# RS14100 register map
File version: 1.0
CPU: CM4 r0p1, little endian, MPU, FPU, 4 interrupt priority bits
Registers are 32-bit, read-write, reset 0x0 unless marked. A register's access mark holds for its fields unless they carry their own. Offsets are from the block's base; [hi:lo] are bit positions; {n}, {i} and the like mark numbered series.

## GSPI0 — GSPI, or Generic SPI, is a module which has been derived from QSPI. GSPI can act only as a master
Base 0x45030000
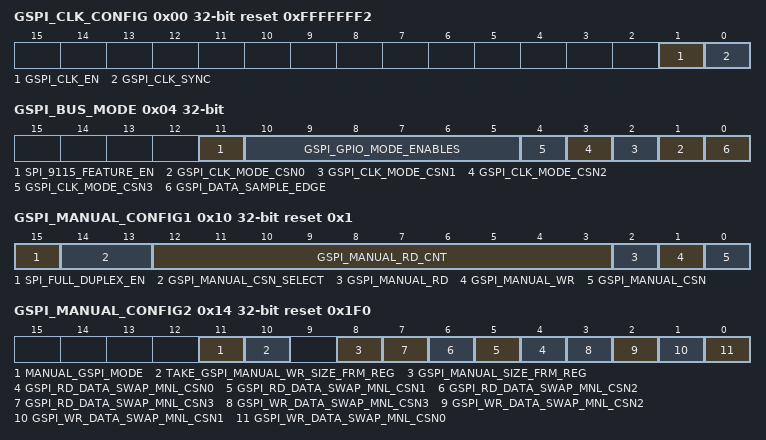
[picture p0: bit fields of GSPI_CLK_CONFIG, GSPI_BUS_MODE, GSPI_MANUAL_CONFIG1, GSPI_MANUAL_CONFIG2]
0x00 GSPI_CLK_CONFIG reset 0xFFFFFFF2 — GSPI Clock Configuration Register
  [1] GSPI_CLK_EN — GSPI clock enable
    0=Disable (Dynamic clock gating is enabled in side GSPI controller); 1=Enable (Full time clock is enabled for GSPI controller.)
  [0] GSPI_CLK_SYNC — If the clock frequency to FLASH (spi_clk) and SOC clk is same.
    0=Disable (Divided SOC clock is connected SCLK. Division value is programmable); 1=Enable (SCLK clock and SOC clock are same)
0x04 GSPI_BUS_MODE (reset mask 0x7FF)
  [11] SPI_9115_FEATURE_EN — 9115 specific features are enabled with this enable
  [10:5] GSPI_GPIO_MODE_ENABLES — These bits are used to map GSPI on GPIO pins
  [n+1] GSPI_CLK_MODE_CSN{n} (n=0..3)
    0=Disable (Mode 0, GSPI_CLK is low when GSPI_CS is high for chip select{n} (csn{n})); 1=Enable (Mode 3, GSPI_CLK is high when GSPI_CS is high for chip select{n} (csn{n}))
  [0] GSPI_DATA_SAMPLE_EDGE — Samples MISO data on clock edges. This should be ZERO for mode3 clock
    0=Disable (Pos edge of loop back spi_pad_clk); 1=Enable (Neg edge of loop back spi_pad_clk)
0x10 GSPI_MANUAL_CONFIG1 reset 0x1 — GSPI Manual Configuration 1 Register
  [15] SPI_FULL_DUPLEX_EN — Full duplex mode enable
    0=Disable (Full duplex mode disabled.); 1=Enable (Full duplex mode enabled)
  [14:13] GSPI_MANUAL_CSN_SELECT — Indicates which CSn is valid. Can be programmable in manual mode
  [12:3] GSPI_MANUAL_RD_CNT — Indicates total number of bytes to be read
  [2] GSPI_MANUAL_RD — Read enable for manual mode when CS is low
  [1] GSPI_MANUAL_WR — Write enable for manual mode when CS is low.
  [0] GSPI_MANUAL_CSN — SPI CS in manual mode
0x14 GSPI_MANUAL_CONFIG2 reset 0x1F0 — GSPI Manual Configuration 2 Register
  [11] MANUAL_GSPI_MODE — Internally the priority is given to manual mode
    0=Disable (SPI mode); 1=Enable (Host SPI mode)
  [10] TAKE_GSPI_MANUAL_WR_SIZE_FRM_REG
    0=Disable (Take write size from Manual config register1[20:19]); 1=Enable (No action)
  [8] GSPI_MANUAL_SIZE_FRM_REG — Manual reads and manual writes
    0=Disable (1 Byte 8 bit mode); 1=Enable (2 Bytes 16 bit mode)
  [n+4] GSPI_RD_DATA_SWAP_MNL_CSN{n} (n=0..3) — Swap the read data inside the GSPI controller it-self.
    0=Disable (Manual read data swap is disabled for csn{n}); 1=Enable (Manual read data swap is enabled for csn{n})
  [3] GSPI_WR_DATA_SWAP_MNL_CSN3 — Swap the write data inside the GSPI controller it-self.
    0=Disable (Manual write data swap is disabled for csn3); 1=Enable (Manual write data swap is enabled for csn3)
  [2] GSPI_WR_DATA_SWAP_MNL_CSN2 — Swap the write data inside the GSPI controller it-self.
    0=Disable (Manual write data swap is disabled for csn2); 1=Enable (Manual write data swap is enabled for csn2)
  [1] GSPI_WR_DATA_SWAP_MNL_CSN1 — Swap the write data inside the GSPI controller it-self.
    0=Disable (Manual write data swap is disabled for csn1); 1=Enable (Manual write data swap is enabled for csn1)
  [0] GSPI_WR_DATA_SWAP_MNL_CSN0 — Swap the write data inside the GSPI controller it-self.
    0=Disable (Manual write data swap is disabled for csn0.); 1=Enable (Manual write data swap is enabled for csn0.)
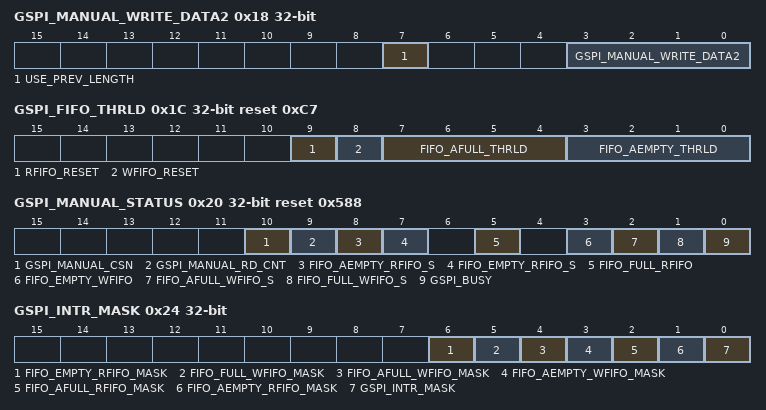
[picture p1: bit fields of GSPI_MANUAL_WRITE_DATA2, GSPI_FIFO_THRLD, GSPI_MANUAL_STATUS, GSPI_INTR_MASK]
0x18 GSPI_MANUAL_WRITE_DATA2
  [7] USE_PREV_LENGTH — Use previous length
    0=Disable (No action); 1=Enable (Uses previously programmed length in [3:0] of this register for next writes)
  [3:0] GSPI_MANUAL_WRITE_DATA2 — Number of bits to be written in write mode
0x1C GSPI_FIFO_THRLD reset 0xC7 — GSPI FIFO Threshold Register
  [9] RFIFO_RESET — read FIFO reset
  [8] WFIFO_RESET — Write FIFO reset
  [7:4] FIFO_AFULL_THRLD — FIFO almost full threshold
  [3:0] FIFO_AEMPTY_THRLD — FIFO almost empty threshold
0x20 GSPI_MANUAL_STATUS ro reset 0x588
  [10] GSPI_MANUAL_CSN — Provide the status of chip select signal
    0=Disable (Active); 1=Enable (Inactive)
  [9] GSPI_MANUAL_RD_CNT — This is a result of 10 bits ORing counter
    0=Disable (No read transactions are in pending); 1=Enable (Read transactions are in pending ( to be done))
  [8] FIFO_AEMPTY_RFIFO_S — Empty status indication for Rfifo in manual mode
  [7] FIFO_EMPTY_RFIFO_S — Empty status indication for Rfifo in manual mode
  [5] FIFO_FULL_RFIFO — Full status indication for Rfifo in manual mode
  [3] FIFO_EMPTY_WFIFO — Empty status indication for Wfifo in manual mode
  [2] FIFO_AFULL_WFIFO_S — Almost full status indication for Wfifo in manual mode
  [1] FIFO_FULL_WFIFO_S — Full status indication for Wfifo in manual mode
  [0] GSPI_BUSY — State of Manual mode
    0=Disable (GSPI controller is IDLE in Manual mode.); 1=Enable (A read, write or dummy cycle operation is in process in manual mode)
0x24 GSPI_INTR_MASK — GSPI Interrupt Mask Register
  [6] FIFO_EMPTY_RFIFO_MASK
    0=Disable (Do not touch); 1=Enable (Read fifo is empty intr mask)
  [5] FIFO_FULL_WFIFO_MASK
    0=Disable (Do not touch); 1=Enable (write fifo full intr mask.)
  [4] FIFO_AFULL_WFIFO_MASK
    0=Disable (Do not touch); 1=Enable (Write fifo almost full intr mask.)
  [3] FIFO_AEMPTY_WFIFO_MASK
    0=Disable (Do not touch); 1=Enable (write fifo almost empty intr mask)
  [2] FIFO_AFULL_RFIFO_MASK
    0=Disable (Do not touch); 1=Enable (read fifo almost full intr mask.)
  [1] FIFO_AEMPTY_RFIFO_MASK
    0=Disable (Do not touch); 1=Enable (Read fifo almost empty intr mask.)
  [0] GSPI_INTR_MASK — GSPI Interrupt mask bit
    0=Disable (Do not touch); 1=Enable (mask the GSPI intr)
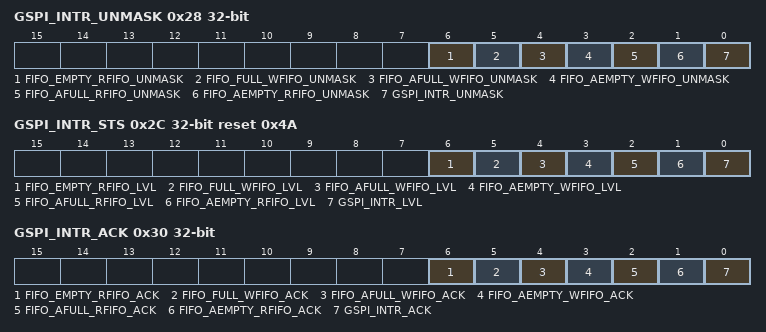
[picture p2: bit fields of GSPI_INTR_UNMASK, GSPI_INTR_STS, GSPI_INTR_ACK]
0x28 GSPI_INTR_UNMASK — GSPI Interrupt Unmask Register
  [6] FIFO_EMPTY_RFIFO_UNMASK
    0=Disable (Do not touch); 1=Enable (Read fifo is empty intr unmask)
  [5] FIFO_FULL_WFIFO_UNMASK
    0=Disable (Do not touch); 1=Enable (write fifo full intr unmask.)
  [4] FIFO_AFULL_WFIFO_UNMASK
    0=Disable (Do not touch); 1=Enable (Write fifo almost full intr unmask.)
  [3] FIFO_AEMPTY_WFIFO_UNMASK
    0=Disable (Do not touch); 1=Enable (write fifo almost empty intr unmask)
  [2] FIFO_AFULL_RFIFO_UNMASK
    0=Disable (Do not touch); 1=Enable (read fifo almost full intr unmask.)
  [1] FIFO_AEMPTY_RFIFO_UNMASK
    0=Disable (Do not touch); 1=Enable (Read fifo almost empty intr unmask.)
  [0] GSPI_INTR_UNMASK — GSPI Interrupt unmask bit
    0=Disable (Do not touch); 1=Enable (unmask the GSPI intr)
0x2C GSPI_INTR_STS ro reset 0x4A — GSPI Interrupt Status Register
  [6] FIFO_EMPTY_RFIFO_LVL
    0=Disable (Read fifo is not empty.); 1=Enable (Read fifo is empty.)
  [5] FIFO_FULL_WFIFO_LVL
    0=Disable (write fifo not full); 1=Enable (write fifo full)
  [4] FIFO_AFULL_WFIFO_LVL
    0=Disable (Wite fifo not reached almost full threshold); 1=Enable (Write fifo almost full threshold)
  [3] FIFO_AEMPTY_WFIFO_LVL
    0=Disable (write fifo not reached almost full threshold.); 1=Enable (write fifo reached almost empty threshold.)
  [2] FIFO_AFULL_RFIFO_LVL
    0=Disable (read fifo do not reach almost full threshold.); 1=Enable (read fifo reached almost full threshold.)
  [1] FIFO_AEMPTY_RFIFO_LVL
    0=Disable (Read fifo does not reach almost empty threshold.); 1=Enable (Read fifo reached almost empty threshold)
  [0] GSPI_INTR_LVL — GSPI Interrupt status bit
    0=Disable (no interrupt); 1=Enable (GSPI raised a interrupt)
0x30 GSPI_INTR_ACK wo — GSPI Interrupt Acknowledge Register
  [6] FIFO_EMPTY_RFIFO_ACK
    0=Disable (Do not touch); 1=Enable (Read fifo is empty intr ack)
  [5] FIFO_FULL_WFIFO_ACK
    0=Disable (Do not touch); 1=Enable (write fifo full intr ack)
  [4] FIFO_AFULL_WFIFO_ACK
    0=Disable (Do not touch); 1=Enable (Write fifo almost full intr ack)
  [3] FIFO_AEMPTY_WFIFO_ACK
    0=Disable (Do not touch); 1=Enable (write fifo reached almost empty intr ack)
  [2] FIFO_AFULL_RFIFO_ACK
    0=Disable (Do not touch); 1=Enable (read fifo reached almost full intr ack)
  [1] FIFO_AEMPTY_RFIFO_ACK
    0=Disable (Do not touch); 1=Enable (Read fifo almost empty intr ack)
  [0] GSPI_INTR_ACK — GSPI Interrupt status bit
    0=Disable (Do not touch); 1=Enable (GSPI intr ack.)
0x34 GSPI_STS_MC ro — GSPI State Machine Monitor Register
  [3:0] BUS_CTRL_PSTATE — Provides SPI bus controller present state
0x38 GSPI_CLK_DIV ro — GSPI Clock Division Factor Register
  [7:0] GSPI_CLK_DIV_FACTOR — Provides GSPI clock division factor to the clock divider, which takes SOC clock as input clock and generates required clock according to division factor
    1=DIVIDER_OUTPUT_CLOCK (divider output clock is gated); 2=DIVIDED_2_CLOCK (provides divided by 2 clock); 3=DIVIDED_4_CLOCK (provides divided by 4 clock); 4=DIVIDED_6_CLOCK (provides divided by 6 clock); 5=DIVIDED_8_CLOCK (provides divided by 8 clock); 6=DIVIDED_10_CLOCK (provides divided by 10 clock)
0x3C GSPI_MANUAL_CONFIG3 ro — GSPI Manual Configuration 3 Register
  [14:0] SPI_MANUAL_RD_LNTHTO_BC — Bits are used to indicate the total number of bytes to read from flash during read operation
